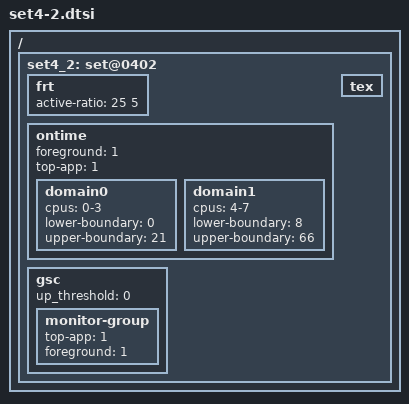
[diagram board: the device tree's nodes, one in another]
/ {
	/* balance mode - app boost */
	set4_2: set@0402{
		frt {	   			/* LIT BIG */
			active-ratio 		= < 25   5>;
		};

		/* Ontime Migration */
		ontime {
			foreground 	= <1>;
			top-app		= <1>;

			domain0 {
				cpus = "0-3";
				lower-boundary = <0>;
				upper-boundary = <21>;
			};
			domain1 {
				cpus = "4-7";
				lower-boundary = <8>;
				upper-boundary = <66>;
			};
		};

		tex { };

		gsc {
			up_threshold = <0>;

			monitor-group {
				top-app = <1>;
				foreground = <1>;
			};
		};
	};
};
